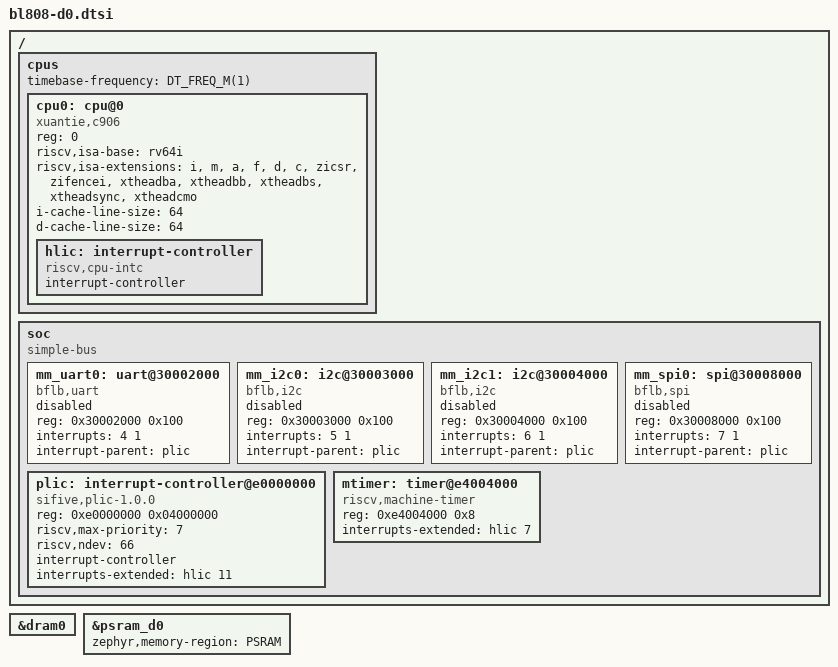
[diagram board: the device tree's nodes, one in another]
/*
 * Copyright (c) 2026 MASSDRIVER EI (massdriver.space)
 *
 * SPDX-License-Identifier: Apache-2.0
 */

#include <bflb/bl808.dtsi>

/ {
	#address-cells = <1>;
	#size-cells = <1>;

	cpus {
		#address-cells = <1>;
		#size-cells = <0>;
		timebase-frequency = <DT_FREQ_M(1)>;

		cpu0: cpu@0 {
			device_type = "cpu";
			compatible = "xuantie,c906", "riscv";
			reg = <0>;
			riscv,isa-base = "rv64i";
			riscv,isa-extensions = "i", "m", "a", "f", "d", "c", "zicsr", "zifencei",
					       "xtheadba", "xtheadbb", "xtheadbs",
					       "xtheadsync", "xtheadcmo";
			i-cache-line-size = <64>;
			d-cache-line-size = <64>;
			status = "okay";

			hlic: interrupt-controller {
				compatible = "riscv,cpu-intc";
				#address-cells = <0>;
				#interrupt-cells = <1>;
				interrupt-controller;
			};
		};
	};

	soc {
		compatible = "simple-bus";
		#address-cells = <1>;
		#size-cells = <1>;
		ranges;

		mm_uart0: uart@30002000 {
			compatible = "bflb,uart";
			reg = <0x30002000 0x100>;
			interrupts = <4 1>;
			interrupt-parent = <&plic>;
			status = "disabled";
		};

		mm_i2c0: i2c@30003000 {
			compatible = "bflb,i2c";
			reg = <0x30003000 0x100>;
			#address-cells = <1>;
			#size-cells = <0>;
			interrupts = <5 1>;
			interrupt-parent = <&plic>;
			status = "disabled";
		};

		mm_i2c1: i2c@30004000 {
			compatible = "bflb,i2c";
			reg = <0x30004000 0x100>;
			#address-cells = <1>;
			#size-cells = <0>;
			interrupts = <6 1>;
			interrupt-parent = <&plic>;
			status = "disabled";
		};

		mm_spi0: spi@30008000 {
			compatible = "bflb,spi";
			reg = <0x30008000 0x100>;
			#address-cells = <1>;
			#size-cells = <0>;
			interrupts = <7 1>;
			interrupt-parent = <&plic>;
			status = "disabled";
		};

		plic: interrupt-controller@e0000000 {
			compatible = "sifive,plic-1.0.0";
			reg = <0xe0000000 0x04000000>;
			riscv,max-priority = <7>;
			riscv,ndev = <66>;
			#address-cells = <0>;
			#interrupt-cells = <2>;
			interrupt-controller;
			interrupts-extended = <&hlic 11>;
		};

		mtimer: timer@e4004000 {
			compatible = "riscv,machine-timer";
			reg = <0xe4004000 0x8>;
			reg-names = "mtimecmp";
			interrupts-extended = <&hlic 7>;
		};
	};
};

all_ram: &dram0 {};

psram: &psram_d0 {
	status = "okay";
	zephyr,memory-region = "PSRAM";
};
